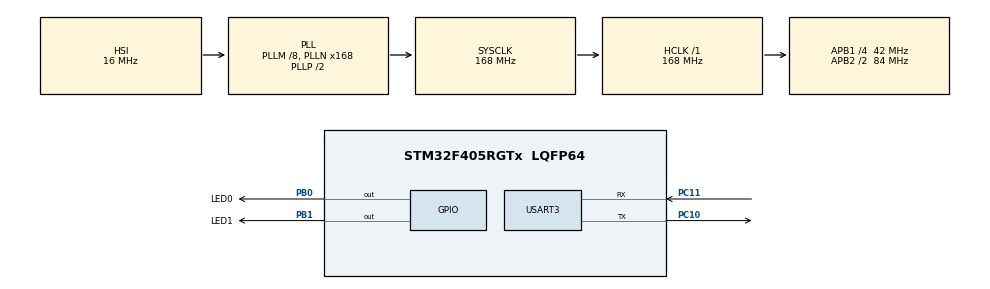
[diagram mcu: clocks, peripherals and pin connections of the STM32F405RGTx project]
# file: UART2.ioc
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FREERTOS.Tasks01=Read_USART,26,128,StartRead,Default,NULL,Dynamic,NULL,NULL;Print_Str,24,128,StartPrint,Default,NULL,Dynamic,NULL,NULL;LED_Control,25,128,StartControl,Default,NULL,Dynamic,NULL,NULL
FREERTOS.configUSE_NEWLIB_REENTRANT=1
Mcu.Family=STM32F4
Mcu.Name=STM32F405RGTx
Mcu.Package=LQFP64
NVIC.PriorityGroup=NVIC_PRIORITYGROUP_4
NVIC.USART3_IRQn=true\:5\:0\:false\:false\:true\:true\:true\:true\:true
PA13.Mode=Serial_Wire
PA13.Signal=SYS_JTMS-SWDIO
PA14.Mode=Serial_Wire
PA14.Signal=SYS_JTCK-SWCLK
PB0.GPIO_Label=LED0
PB0.Signal=GPIO_Output
PB1.GPIO_Label=LED1
PB1.Signal=GPIO_Output
PC10.Mode=Asynchronous
PC10.Signal=USART3_TX
PC11.Mode=Asynchronous
PC11.Signal=USART3_RX
PH0-OSC_IN.Mode=HSE-External-Oscillator
PH0-OSC_IN.Signal=RCC_OSC_IN
PH1-OSC_OUT.Mode=HSE-External-Oscillator
PH1-OSC_OUT.Signal=RCC_OSC_OUT
ProjectManager.HeapSize=0x200
ProjectManager.StackSize=0x400
ProjectManager.TargetToolchain=STM32CubeIDE
RCC.48MHZClocksFreq_Value=84000000
RCC.AHBFreq_Value=168000000
RCC.APB1CLKDivider=RCC_HCLK_DIV4
RCC.APB1Freq_Value=42000000
RCC.APB1TimFreq_Value=84000000
RCC.APB2CLKDivider=RCC_HCLK_DIV2
RCC.APB2Freq_Value=84000000
RCC.APB2TimFreq_Value=168000000
RCC.CortexFreq_Value=168000000
RCC.HCLKFreq_Value=168000000
RCC.HSE_VALUE=8000000
RCC.HSI_VALUE=16000000
RCC.LSE_VALUE=32768
RCC.PLLM=8
RCC.PLLN=168
RCC.SYSCLKFreq_VALUE=168000000
RCC.SYSCLKSource=RCC_SYSCLKSOURCE_PLLCLK
RCC.VCOOutputFreq_Value=336000000
USART3.VirtualMode=VM_ASYNC
VP_FREERTOS_VS_CMSIS_V2.Mode=CMSIS_V2
board=custom

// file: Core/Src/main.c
/* USER CODE BEGIN Header */
/**
  ******************************************************************************
  * @file           : main.c
  * @brief          : Main program body
  ******************************************************************************
  * @attention
  *
  * Copyright (c) 2022 STMicroelectronics.
  * All rights reserved.
  *
  * This software is licensed under terms that can be found in the LICENSE file
  * in the root directory of this software component.
  * If no LICENSE file comes with this software, it is provided AS-IS.
  *
  ******************************************************************************
  */
/* USER CODE END Header */
#include "main.h"
#include "cmsis_os.h"

UART_HandleTypeDef huart3;

/* Definitions for Read_USART */
osThreadId_t Read_USARTHandle;
const osThreadAttr_t Read_USART_attributes = {
  .name = "Read_USART",
  .stack_size = 128 * 4,
  .priority = (osPriority_t) osPriorityNormal2,
};
/* Definitions for Print_Str */
osThreadId_t Print_StrHandle;
const osThreadAttr_t Print_Str_attributes = {
  .name = "Print_Str",
  .stack_size = 128 * 4,
  .priority = (osPriority_t) osPriorityNormal,
};
/* Definitions for LED_Control */
osThreadId_t LED_ControlHandle;
const osThreadAttr_t LED_Control_attributes = {
  .name = "LED_Control",
  .stack_size = 128 * 4,
  .priority = (osPriority_t) osPriorityNormal1,
};

void SystemClock_Config(void);
static void MX_GPIO_Init(void);
static void MX_USART3_UART_Init(void);
void StartRead(void *argument);
void StartPrint(void *argument);
void StartControl(void *argument);

/* USER CODE BEGIN 0 */
uint8_t rx_data;
uint8_t tx_data[30]="Program's running...\r\n";

void HAL_UART_RxCpltCallback(UART_HandleTypeDef *huart){
    if(huart->Instance == USART3){
        HAL_UART_Transmit(&huart3,&rx_data,sizeof(rx_data), 100);
        HAL_UART_Receive_IT(&huart3, &rx_data, 1);
    }
}
/* USER CODE END 0 */

int main(void)
{

  /* MCU Configuration--------------------------------------------------------*/

  /* Reset of all peripherals, Initializes the Flash interface and the Systick. */
  HAL_Init();

  /* Configure the system clock */
  SystemClock_Config();

  /* Initialize all configured peripherals */
  MX_GPIO_Init();
  MX_USART3_UART_Init();

  /* Init scheduler */
  osKernelInitialize();

  /* Create the thread(s) */
  /* creation of Read_USART */
  Read_USARTHandle = osThreadNew(StartRead, NULL, &Read_USART_attributes);

  /* creation of Print_Str */
  Print_StrHandle = osThreadNew(StartPrint, NULL, &Print_Str_attributes);

  /* creation of LED_Control */
  LED_ControlHandle = osThreadNew(StartControl, NULL, &LED_Control_attributes);

  /* Start scheduler */
  osKernelStart();

  /* We should never get here as control is now taken by the scheduler */
  /* Infinite loop */
  while (1)
  {

    /* USER CODE BEGIN 3 */
	  HAL_GPIO_TogglePin(LED1_GPIO_Port, LED1_Pin);
//	  HAL_UART_Transmit(&huart3,tx_data, sizeof(tx_data), 1000);
	  HAL_Delay(500);
  }
  /* USER CODE END 3 */
}

void SystemClock_Config(void)
{
  RCC_OscInitTypeDef RCC_OscInitStruct = {0};
  RCC_ClkInitTypeDef RCC_ClkInitStruct = {0};

  /** Configure the main internal regulator output voltage
  */
  __HAL_RCC_PWR_CLK_ENABLE();
  __HAL_PWR_VOLTAGESCALING_CONFIG(PWR_REGULATOR_VOLTAGE_SCALE1);

  /** Initializes the RCC Oscillators according to the specified parameters
  * in the RCC_OscInitTypeDef structure.
  */
  RCC_OscInitStruct.OscillatorType = RCC_OSCILLATORTYPE_HSI;
  RCC_OscInitStruct.HSIState = RCC_HSI_ON;
  RCC_OscInitStruct.HSICalibrationValue = RCC_HSICALIBRATION_DEFAULT;
  RCC_OscInitStruct.PLL.PLLState = RCC_PLL_ON;
  RCC_OscInitStruct.PLL.PLLSource = RCC_PLLSOURCE_HSI;
  RCC_OscInitStruct.PLL.PLLM = 8;
  RCC_OscInitStruct.PLL.PLLN = 168;
  RCC_OscInitStruct.PLL.PLLP = RCC_PLLP_DIV2;
  RCC_OscInitStruct.PLL.PLLQ = 4;
  if (HAL_RCC_OscConfig(&RCC_OscInitStruct) != HAL_OK)
  {
    Error_Handler();
  }

  /** Initializes the CPU, AHB and APB buses clocks
  */
  RCC_ClkInitStruct.ClockType = RCC_CLOCKTYPE_HCLK|RCC_CLOCKTYPE_SYSCLK
                              |RCC_CLOCKTYPE_PCLK1|RCC_CLOCKTYPE_PCLK2;
  RCC_ClkInitStruct.SYSCLKSource = RCC_SYSCLKSOURCE_PLLCLK;
  RCC_ClkInitStruct.AHBCLKDivider = RCC_SYSCLK_DIV1;
  RCC_ClkInitStruct.APB1CLKDivider = RCC_HCLK_DIV4;
  RCC_ClkInitStruct.APB2CLKDivider = RCC_HCLK_DIV2;

  if (HAL_RCC_ClockConfig(&RCC_ClkInitStruct, FLASH_LATENCY_5) != HAL_OK)
  {
    Error_Handler();
  }
}

static void MX_USART3_UART_Init(void)
{

  huart3.Instance = USART3;
  huart3.Init.BaudRate = 115200;
  huart3.Init.WordLength = UART_WORDLENGTH_8B;
  huart3.Init.StopBits = UART_STOPBITS_1;
  huart3.Init.Parity = UART_PARITY_NONE;
  huart3.Init.Mode = UART_MODE_TX_RX;
  huart3.Init.HwFlowCtl = UART_HWCONTROL_NONE;
  huart3.Init.OverSampling = UART_OVERSAMPLING_16;
  if (HAL_UART_Init(&huart3) != HAL_OK)
  {
    Error_Handler();
  }

}

static void MX_GPIO_Init(void)
{
  GPIO_InitTypeDef GPIO_InitStruct = {0};

  /* GPIO Ports Clock Enable */
  __HAL_RCC_GPIOH_CLK_ENABLE();
  __HAL_RCC_GPIOB_CLK_ENABLE();
  __HAL_RCC_GPIOA_CLK_ENABLE();
  __HAL_RCC_GPIOC_CLK_ENABLE();

  /*Configure GPIO pin Output Level */
  HAL_GPIO_WritePin(GPIOB, LED0_Pin|LED1_Pin, GPIO_PIN_RESET);

  /*Configure GPIO pins : LED0_Pin LED1_Pin */
  GPIO_InitStruct.Pin = LED0_Pin|LED1_Pin;
  GPIO_InitStruct.Mode = GPIO_MODE_OUTPUT_PP;
  GPIO_InitStruct.Pull = GPIO_NOPULL;
  GPIO_InitStruct.Speed = GPIO_SPEED_FREQ_LOW;
  HAL_GPIO_Init(GPIOB, &GPIO_InitStruct);

}

void StartRead(void *argument)
{
  for(;;)
  {
    osDelay(1);
  }
}

void StartPrint(void *argument)
{
  /* USER CODE BEGIN StartPrint */
  /* Infinite loop */
  for(;;)
  {
    osDelay(500);
  }
  /* USER CODE END StartPrint */
}

void StartControl(void *argument)
{
  for(;;)
  {
    osDelay(1);
  }
}

void Error_Handler(void)
{
  __disable_irq();
  while (1)
  {
  }
}
